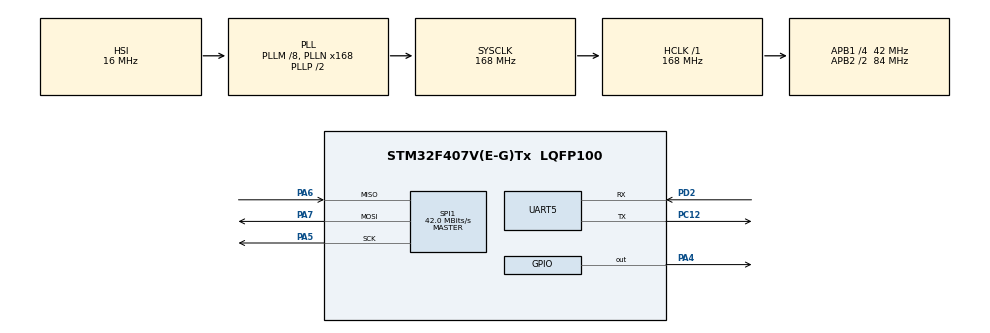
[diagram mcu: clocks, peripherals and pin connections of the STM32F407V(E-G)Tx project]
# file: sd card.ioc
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FATFS._MAX_SS=4096
FATFS._USE_LFN=1
Mcu.Family=STM32F4
Mcu.Name=STM32F407V(E-G)Tx
Mcu.Package=LQFP100
NVIC.PriorityGroup=NVIC_PRIORITYGROUP_0
PA13.Mode=Serial_Wire
PA13.Signal=SYS_JTMS-SWDIO
PA14.Mode=Serial_Wire
PA14.Signal=SYS_JTCK-SWCLK
PA4.Signal=GPIO_Output
PA5.Mode=Full_Duplex_Master
PA5.Signal=SPI1_SCK
PA6.Mode=Full_Duplex_Master
PA6.Signal=SPI1_MISO
PA7.Mode=Full_Duplex_Master
PA7.Signal=SPI1_MOSI
PC12.Mode=Asynchronous
PC12.Signal=UART5_TX
PD2.Mode=Asynchronous
PD2.Signal=UART5_RX
ProjectManager.HeapSize=0x200
ProjectManager.StackSize=0x400
ProjectManager.TargetToolchain=STM32CubeIDE
RCC.48MHZClocksFreq_Value=48000000
RCC.AHBFreq_Value=168000000
RCC.APB1CLKDivider=RCC_HCLK_DIV4
RCC.APB1Freq_Value=42000000
RCC.APB1TimFreq_Value=84000000
RCC.APB2CLKDivider=RCC_HCLK_DIV2
RCC.APB2Freq_Value=84000000
RCC.APB2TimFreq_Value=168000000
RCC.CortexFreq_Value=168000000
RCC.HCLKFreq_Value=168000000
RCC.HSE_VALUE=8000000
RCC.HSI_VALUE=16000000
RCC.LSE_VALUE=32768
RCC.PLLM=8
RCC.PLLN=168
RCC.PLLQ=7
RCC.SYSCLKFreq_VALUE=168000000
RCC.SYSCLKSource=RCC_SYSCLKSOURCE_PLLCLK
RCC.VCOOutputFreq_Value=336000000
SPI1.CalculateBaudRate=42.0 MBits/s
SPI1.Direction=SPI_DIRECTION_2LINES
SPI1.Mode=SPI_MODE_MASTER
SPI1.VirtualType=VM_MASTER
UART5.VirtualMode=Asynchronous
VP_FATFS_VS_Generic.Mode=User_defined
board=STM32F407G-DISC1

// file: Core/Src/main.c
/* USER CODE BEGIN Header */
/**
 ******************************************************************************
 * @file           : main.c
 * @brief          : Main program body
 ******************************************************************************
 * @attention
 *
 * Copyright (c) 2024 STMicroelectronics.
 * All rights reserved.
 *
 * This software is licensed under terms that can be found in the LICENSE file
 * in the root directory of this software component.
 * If no LICENSE file comes with this software, it is provided AS-IS.
 *
 ******************************************************************************
 */
/* USER CODE END Header */
#include "main.h"
#include "fatfs.h"

/* USER CODE BEGIN Includes */
#include<stdio.h>
/* USER CODE END Includes */

SPI_HandleTypeDef hspi1;

UART_HandleTypeDef huart5;

/* USER CODE BEGIN PV */
// FatFS object variables
FATFS fs;    // File system object
FRESULT res; // Result code

/* USER CODE END PV */

void SystemClock_Config(void);
static void MX_GPIO_Init(void);
static void MX_SPI1_Init(void);
static void MX_UART5_Init(void);

/* USER CODE BEGIN 0 */
int _write(int file, char *ptr, int len) {
	HAL_UART_Transmit(&huart5, (uint8_t*) ptr, len, 100);
	return len;
}

/* USER CODE END 0 */

int main(void)
{

  /* MCU Configuration--------------------------------------------------------*/

  /* Reset of all peripherals, Initializes the Flash interface and the Systick. */
  HAL_Init();

  /* Configure the system clock */
  SystemClock_Config();

  /* Initialize all configured peripherals */
  MX_GPIO_Init();
  MX_SPI1_Init();
  MX_FATFS_Init();
  MX_UART5_Init();
  /* USER CODE BEGIN 2 */
	// Mount the file system
//	    if (f_mount(&SDFatFs, SDPath, 1) == FR_OK)
//	    {
//	    	printf("F mount success!");
//	        // Create and open a new file for writing
//	        if (f_open(&MyFile, "0:STM32.TXT", FA_CREATE_ALWAYS | FA_WRITE) == FR_OK)
//	        {
//	        	printf("F open success!");
//	            UINT byteswritten;
//	            char wtext[] = "Hello STM32!";
//
//	            // Write data to the file
//	            f_write(&MyFile, wtext, sizeof(wtext) - 1, &byteswritten);
//	            printf("F write success!");
//
//	            // Close the file
//	            f_close(&MyFile);
//	            printf("F close success!");
//	        }
//
//	        // Open the file for reading
//	        if (f_open(&MyFile, "0:STM32.TXT", FA_READ) == FR_OK)
//	        {
//	            UINT bytesread;
//	            char rtext[100];
//
//	            // Read data from the file
//	            f_read(&MyFile, rtext, sizeof(rtext) - 1, &bytesread);
//	            printf("F read success!");
//	            // Close the file
//	            f_close(&MyFile);
//	            printf("F read close success!");
//	        }
//
//	        // Delete the file
//	        //f_unlink("0:STM32.TXT");
//	    }
//	    else
//	    {
//	    	   printf("Bad communication!");
//
//	    }

  /* USER CODE END 2 */

  /* Infinite loop */
	while (1) {

    /* USER CODE BEGIN 3 */
		printf("Starting...\n\r");
		// Mount the SD card
		res = f_mount(&fs, "", 1);
		if (res == FR_OK) {
			// Mount was successful
			printf("Mount was successful\n\r");
		} else {
			// Mount failed
			printf("Mount failed\n\r : %u",res);

		}
		HAL_Delay(3000);
	}

  /* USER CODE END 3 */
}

void SystemClock_Config(void)
{
  RCC_OscInitTypeDef RCC_OscInitStruct = {0};
  RCC_ClkInitTypeDef RCC_ClkInitStruct = {0};

  /** Configure the main internal regulator output voltage
  */
  __HAL_RCC_PWR_CLK_ENABLE();
  __HAL_PWR_VOLTAGESCALING_CONFIG(PWR_REGULATOR_VOLTAGE_SCALE1);

  /** Initializes the RCC Oscillators according to the specified parameters
  * in the RCC_OscInitTypeDef structure.
  */
  RCC_OscInitStruct.OscillatorType = RCC_OSCILLATORTYPE_HSI;
  RCC_OscInitStruct.HSIState = RCC_HSI_ON;
  RCC_OscInitStruct.HSICalibrationValue = RCC_HSICALIBRATION_DEFAULT;
  RCC_OscInitStruct.PLL.PLLState = RCC_PLL_ON;
  RCC_OscInitStruct.PLL.PLLSource = RCC_PLLSOURCE_HSI;
  RCC_OscInitStruct.PLL.PLLM = 8;
  RCC_OscInitStruct.PLL.PLLN = 168;
  RCC_OscInitStruct.PLL.PLLP = RCC_PLLP_DIV2;
  RCC_OscInitStruct.PLL.PLLQ = 7;
  if (HAL_RCC_OscConfig(&RCC_OscInitStruct) != HAL_OK)
  {
    Error_Handler();
  }

  /** Initializes the CPU, AHB and APB buses clocks
  */
  RCC_ClkInitStruct.ClockType = RCC_CLOCKTYPE_HCLK|RCC_CLOCKTYPE_SYSCLK
                              |RCC_CLOCKTYPE_PCLK1|RCC_CLOCKTYPE_PCLK2;
  RCC_ClkInitStruct.SYSCLKSource = RCC_SYSCLKSOURCE_PLLCLK;
  RCC_ClkInitStruct.AHBCLKDivider = RCC_SYSCLK_DIV1;
  RCC_ClkInitStruct.APB1CLKDivider = RCC_HCLK_DIV4;
  RCC_ClkInitStruct.APB2CLKDivider = RCC_HCLK_DIV2;

  if (HAL_RCC_ClockConfig(&RCC_ClkInitStruct, FLASH_LATENCY_5) != HAL_OK)
  {
    Error_Handler();
  }
}

static void MX_SPI1_Init(void)
{

  /* SPI1 parameter configuration*/
  hspi1.Instance = SPI1;
  hspi1.Init.Mode = SPI_MODE_MASTER;
  hspi1.Init.Direction = SPI_DIRECTION_2LINES;
  hspi1.Init.DataSize = SPI_DATASIZE_8BIT;
  hspi1.Init.CLKPolarity = SPI_POLARITY_LOW;
  hspi1.Init.CLKPhase = SPI_PHASE_1EDGE;
  hspi1.Init.NSS = SPI_NSS_SOFT;
  hspi1.Init.BaudRatePrescaler = SPI_BAUDRATEPRESCALER_2;
  hspi1.Init.FirstBit = SPI_FIRSTBIT_MSB;
  hspi1.Init.TIMode = SPI_TIMODE_DISABLE;
  hspi1.Init.CRCCalculation = SPI_CRCCALCULATION_DISABLE;
  hspi1.Init.CRCPolynomial = 10;
  if (HAL_SPI_Init(&hspi1) != HAL_OK)
  {
    Error_Handler();
  }

}

static void MX_UART5_Init(void)
{

  huart5.Instance = UART5;
  huart5.Init.BaudRate = 115200;
  huart5.Init.WordLength = UART_WORDLENGTH_8B;
  huart5.Init.StopBits = UART_STOPBITS_1;
  huart5.Init.Parity = UART_PARITY_NONE;
  huart5.Init.Mode = UART_MODE_TX_RX;
  huart5.Init.HwFlowCtl = UART_HWCONTROL_NONE;
  huart5.Init.OverSampling = UART_OVERSAMPLING_16;
  if (HAL_UART_Init(&huart5) != HAL_OK)
  {
    Error_Handler();
  }

}

static void MX_GPIO_Init(void)
{
  GPIO_InitTypeDef GPIO_InitStruct = {0};

  /* GPIO Ports Clock Enable */
  __HAL_RCC_GPIOA_CLK_ENABLE();
  __HAL_RCC_GPIOC_CLK_ENABLE();
  __HAL_RCC_GPIOD_CLK_ENABLE();

  /*Configure GPIO pin Output Level */
  HAL_GPIO_WritePin(GPIOA, GPIO_PIN_4, GPIO_PIN_RESET);

  /*Configure GPIO pin : PA4 */
  GPIO_InitStruct.Pin = GPIO_PIN_4;
  GPIO_InitStruct.Mode = GPIO_MODE_OUTPUT_PP;
  GPIO_InitStruct.Pull = GPIO_NOPULL;
  GPIO_InitStruct.Speed = GPIO_SPEED_FREQ_LOW;
  HAL_GPIO_Init(GPIOA, &GPIO_InitStruct);

}

void Error_Handler(void)
{
	__disable_irq();
	while (1) {
	}
}
